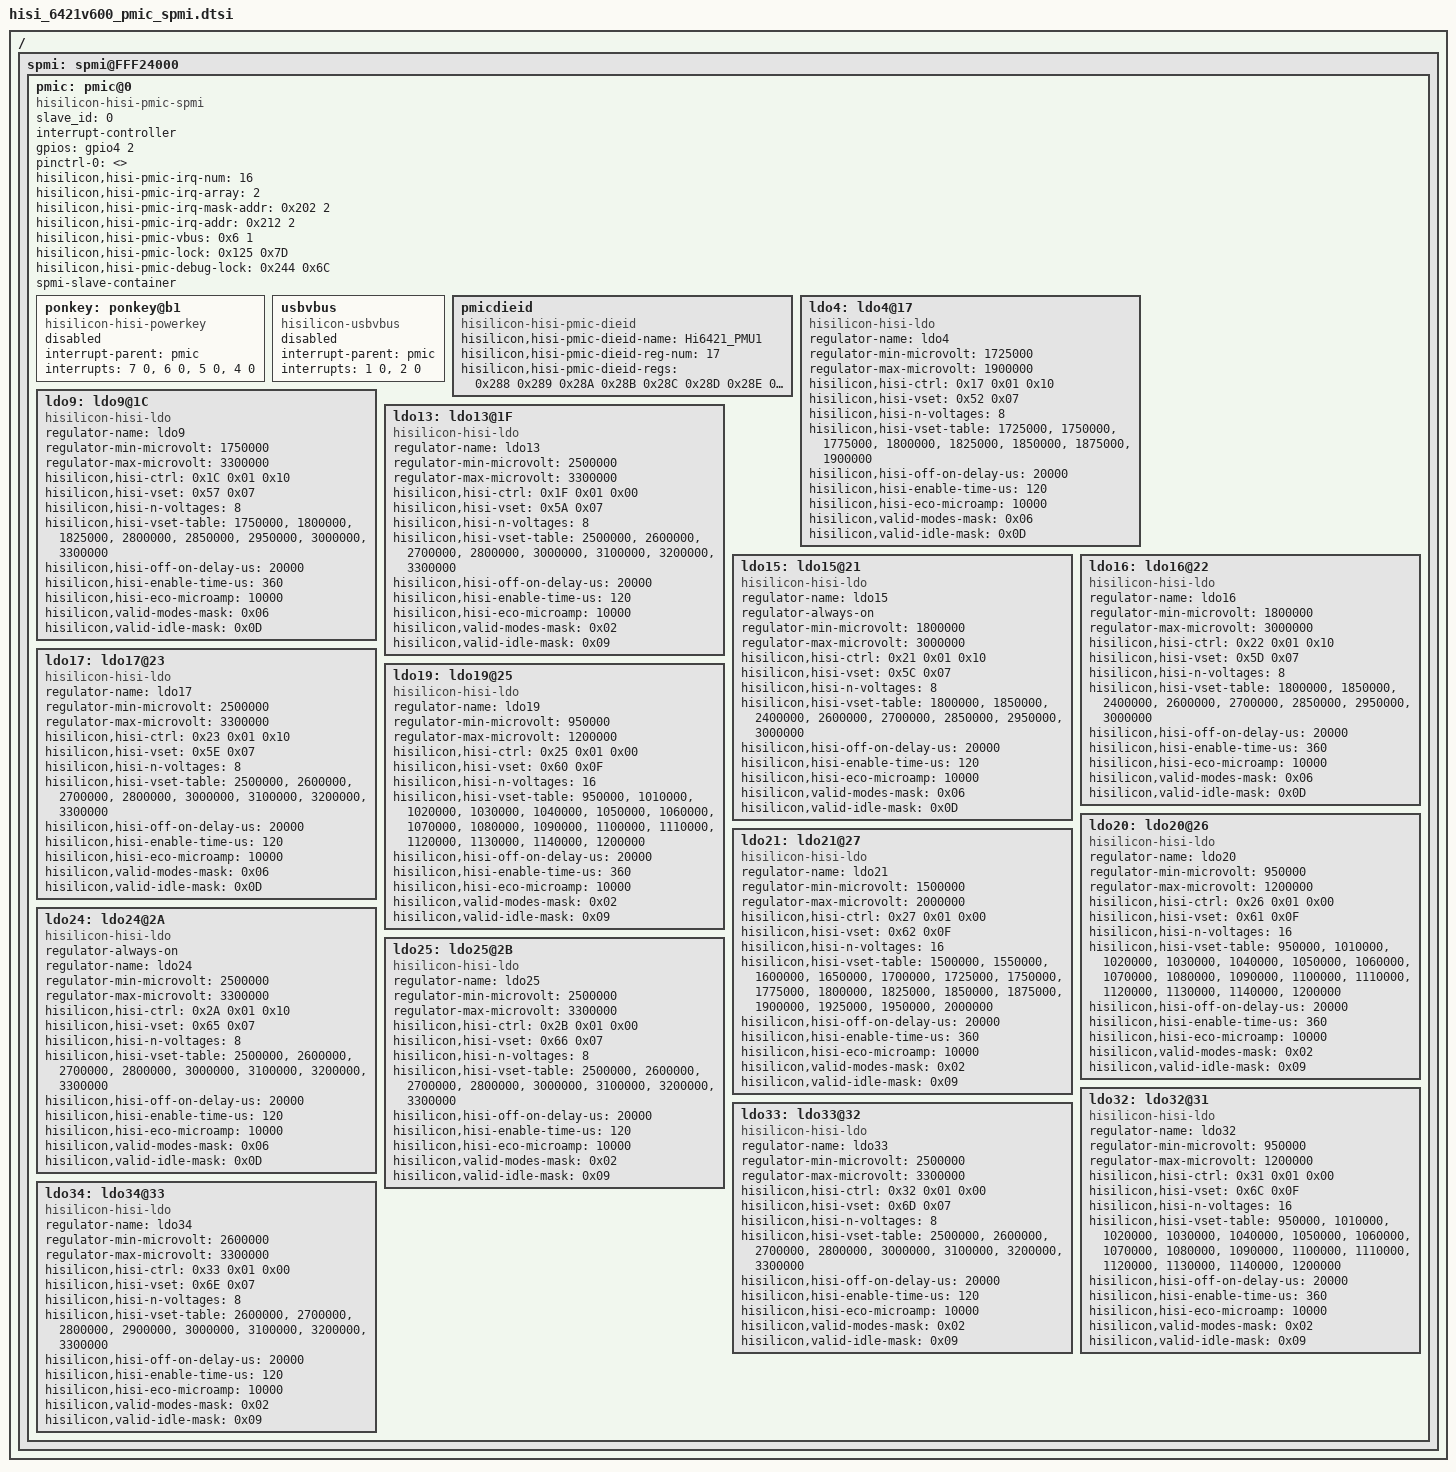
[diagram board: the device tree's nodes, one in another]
/*
 *  Copyright (C) 2012-2013 Linaro Ltd.
 *
 *  This program is free software; you can redistribute it and/or modify
 *  it under the terms of the GNU General Public License version 2 as
 *  publishhed by the Free Software Foundation.
 */
 /*hisilicon,valid-modes-mask:
*#define REGULATOR_MODE_FAST                     0x1
*#define REGULATOR_MODE_NORMAL                   0x2
*#define REGULATOR_MODE_IDLE                     0x4
*#define REGULATOR_MODE_STANDBY                  0x8
*/
/*hisilicon,valid-idle-mask:
*#define REGULATOR_CHANGE_VOLTAGE        0x1
*#define REGULATOR_CHANGE_CURRENT        0x2
*#define REGULATOR_CHANGE_MODE           0x4
*#define REGULATOR_CHANGE_STATUS         0x8
*#define REGULATOR_CHANGE_DRMS           0x10
*#define REGULATOR_CHANGE_BYPASS         0x20
*/
/ {
	spmi: spmi@FFF24000 {
		pmic: pmic@0 {
			compatible = "hisilicon-hisi-pmic-spmi";
			slave_id = <0>;
			#interrupt-cells = <2>;
			interrupt-controller;
			gpios = <&gpio4 2 0>;
			pinctrl-names = "default";
			pinctrl-0 = <>;
			hisilicon,hisi-pmic-irq-num = <16>;/*hisi irq number*/
			hisilicon,hisi-pmic-irq-array = <2>;/*hisi irq array*/
			hisilicon,hisi-pmic-irq-mask-addr = <0x202 2>;/*hisi irq mask addr*/
			hisilicon,hisi-pmic-irq-addr = <0x212 2>;/*hisi irq addr*/
			hisilicon,hisi-pmic-vbus = <0x6 1>;/*vbus status addr and bit*/
			hisilicon,hisi-pmic-lock = <0x125 0x7D>; /*lock: <addr value>*/
			hisilicon,hisi-pmic-debug-lock = <0x244 0x6C>;/*debug-lock: <addr value>*/
			spmi-slave-container;/*spmi-dev-container;*/

			ponkey:ponkey@b1{
					compatible = "hisilicon-hisi-powerkey";
					interrupt-parent = <&pmic>;
					interrupts = <7 0>, <6 0>, <5 0>, <4 0>;
					interrupt-names = "down", "up", "hold 1s", "hold 6s";
					status = "disabled";
			};

			usbvbus {
				compatible = "hisilicon-usbvbus";
				interrupt-parent = <&pmic>;
				interrupts = <1 0>, <2 0>;
				interrupt-names = "connect", "disconnect";
				status = "disabled";
			};

			pmicdieid {
				compatible = "hisilicon-hisi-pmic-dieid";
				hisilicon,hisi-pmic-dieid-name = "Hi6421_PMU1"; /*dieid: <chip name>*/
				hisilicon,hisi-pmic-dieid-reg-num = <17>; /*dieid: <register number>*/
				hisilicon,hisi-pmic-dieid-regs = <0x288 0x289 0x28A 0x28B 0x28C 0x28D 0x28E 0x28F 0x290 0x291 0x292 0x293 0x294 0x295 0x296 0x297 0x298>; /*dieid: <addr value>*/
			};

			ldo4: ldo4@17 {
				compatible = "hisilicon-hisi-ldo";
				regulator-name = "ldo4";
				regulator-min-microvolt = <1725000>;
				regulator-max-microvolt = <1900000>;
				hisilicon,hisi-ctrl = <0x17 0x01 0x10>;/*ctrl_reg、enable_mask、eco_mode_mask*/
				hisilicon,hisi-vset = <0x52 0x07>;
				hisilicon,hisi-n-voltages = <8>;
				hisilicon,hisi-vset-table = <1725000>, <1750000>,
											<1775000>, <1800000>,
											<1825000>, <1850000>,
											<1875000>, <1900000>;
				hisilicon,hisi-off-on-delay-us = <20000>;
				hisilicon,hisi-enable-time-us = <120>;
				hisilicon,hisi-eco-microamp = <10000>;
				hisilicon,valid-modes-mask = <0x06>;
				hisilicon,valid-idle-mask = <0x0D>;
			};

			ldo9: ldo9@1C {
				compatible = "hisilicon-hisi-ldo";
				regulator-name = "ldo9";
				regulator-min-microvolt = <1750000>;
				regulator-max-microvolt = <3300000>;
				hisilicon,hisi-ctrl = <0x1C 0x01 0x10>;
				hisilicon,hisi-vset = <0x57 0x07>;
				hisilicon,hisi-n-voltages = <8>;
				hisilicon,hisi-vset-table = <1750000>, <1800000>,
											<1825000>, <2800000>,
											<2850000>, <2950000>,
											<3000000>, <3300000>;
				hisilicon,hisi-off-on-delay-us = <20000>;
				hisilicon,hisi-enable-time-us = <360>;
				hisilicon,hisi-eco-microamp = <10000>;
				hisilicon,valid-modes-mask = <0x06>;
				hisilicon,valid-idle-mask = <0x0D>;
			};

			ldo13: ldo13@1F {
				compatible = "hisilicon-hisi-ldo";
				regulator-name = "ldo13";
				regulator-min-microvolt = <2500000>;
				regulator-max-microvolt = <3300000>;
				hisilicon,hisi-ctrl = <0x1F 0x01 0x00>;
				hisilicon,hisi-vset = <0x5A 0x07>;
				hisilicon,hisi-n-voltages = <8>;
				hisilicon,hisi-vset-table = <2500000>, <2600000>,
											<2700000>, <2800000>,
											<3000000>, <3100000>,
											<3200000>, <3300000>;
				hisilicon,hisi-off-on-delay-us = <20000>;
				hisilicon,hisi-enable-time-us = <120>;
				hisilicon,hisi-eco-microamp = <10000>;
				hisilicon,valid-modes-mask = <0x02>;
				hisilicon,valid-idle-mask = <0x09>;
			};


			ldo15: ldo15@21 {
				compatible = "hisilicon-hisi-ldo";
				regulator-name = "ldo15";
				regulator-always-on;
				regulator-min-microvolt = <1800000>;
				regulator-max-microvolt = <3000000>;
				hisilicon,hisi-ctrl = <0x21 0x01 0x10>;
				hisilicon,hisi-vset = <0x5C 0x07>;
				hisilicon,hisi-n-voltages = <8>;
				hisilicon,hisi-vset-table = <1800000>, <1850000>,
											<2400000>, <2600000>,
											<2700000>, <2850000>,
											<2950000>, <3000000>;
				hisilicon,hisi-off-on-delay-us = <20000>;
				hisilicon,hisi-enable-time-us = <120>;
				hisilicon,hisi-eco-microamp = <10000>;
				hisilicon,valid-modes-mask = <0x06>;
				hisilicon,valid-idle-mask = <0x0D>;
			};

			ldo16: ldo16@22 {
				compatible = "hisilicon-hisi-ldo";
				regulator-name = "ldo16";
				regulator-min-microvolt = <1800000>;
				regulator-max-microvolt = <3000000>;
				hisilicon,hisi-ctrl = <0x22 0x01 0x10>;
				hisilicon,hisi-vset = <0x5D 0x07>;
				hisilicon,hisi-n-voltages = <8>;
				hisilicon,hisi-vset-table = <1800000>, <1850000>,
											<2400000>, <2600000>,
											<2700000>, <2850000>,
											<2950000>, <3000000>;
				hisilicon,hisi-off-on-delay-us = <20000>;
				hisilicon,hisi-enable-time-us = <360>;
				hisilicon,hisi-eco-microamp = <10000>;
				hisilicon,valid-modes-mask = <0x06>;
				hisilicon,valid-idle-mask = <0x0D>;
			};

			ldo17: ldo17@23 {
				compatible = "hisilicon-hisi-ldo";
				regulator-name = "ldo17";
				regulator-min-microvolt = <2500000>;
				regulator-max-microvolt = <3300000>;
				hisilicon,hisi-ctrl = <0x23 0x01 0x10>;
				hisilicon,hisi-vset = <0x5E 0x07>;
				hisilicon,hisi-n-voltages = <8>;
				hisilicon,hisi-vset-table = <2500000>, <2600000>,
											<2700000>, <2800000>,
											<3000000>, <3100000>,
											<3200000>, <3300000>;
				hisilicon,hisi-off-on-delay-us = <20000>;
				hisilicon,hisi-enable-time-us = <120>;
				hisilicon,hisi-eco-microamp = <10000>;
				hisilicon,valid-modes-mask = <0x06>;
				hisilicon,valid-idle-mask = <0x0D>;
			};

			ldo19: ldo19@25 {
				compatible = "hisilicon-hisi-ldo";
				regulator-name = "ldo19";
				regulator-min-microvolt = <950000>;
				regulator-max-microvolt = <1200000>;
				hisilicon,hisi-ctrl = <0x25 0x01 0x00>;
				hisilicon,hisi-vset = <0x60 0x0F>;
				hisilicon,hisi-n-voltages = <16>;
				hisilicon,hisi-vset-table = <950000>,  <1010000>,
											<1020000>,  <1030000>,
											<1040000>, <1050000>,
											<1060000>, <1070000>,
											<1080000>, <1090000>,
											<1100000>, <1110000>,
											<1120000>, <1130000>,
											<1140000>, <1200000>;
				hisilicon,hisi-off-on-delay-us = <20000>;
				hisilicon,hisi-enable-time-us = <360>;
				hisilicon,hisi-eco-microamp = <10000>;
				hisilicon,valid-modes-mask = <0x02>;
				hisilicon,valid-idle-mask = <0x09>;
			};

			ldo20: ldo20@26 {
				compatible = "hisilicon-hisi-ldo";
				regulator-name = "ldo20";
				regulator-min-microvolt = <950000>;
				regulator-max-microvolt = <1200000>;
				hisilicon,hisi-ctrl = <0x26 0x01 0x00>;
				hisilicon,hisi-vset = <0x61 0x0F>;
				hisilicon,hisi-n-voltages = <16>;
				hisilicon,hisi-vset-table = <950000>,  <1010000>,
											<1020000>,  <1030000>,
											<1040000>, <1050000>,
											<1060000>, <1070000>,
											<1080000>, <1090000>,
											<1100000>, <1110000>,
											<1120000>, <1130000>,
											<1140000>, <1200000>;
				hisilicon,hisi-off-on-delay-us = <20000>;
				hisilicon,hisi-enable-time-us = <360>;
				hisilicon,hisi-eco-microamp = <10000>;
				hisilicon,valid-modes-mask = <0x02>;
				hisilicon,valid-idle-mask = <0x09>;
			};

			ldo21: ldo21@27 {
				compatible = "hisilicon-hisi-ldo";
				regulator-name = "ldo21";
				regulator-min-microvolt = <1500000>;
				regulator-max-microvolt = <2000000>;
				hisilicon,hisi-ctrl = <0x27 0x01 0x00>;
				hisilicon,hisi-vset = <0x62 0x0F>;
				hisilicon,hisi-n-voltages = <16>;
				hisilicon,hisi-vset-table =  <1500000>,  <1550000>,
											<1600000>,  <1650000>,
											<1700000>, <1725000>,
											<1750000>, <1775000>,
											<1800000>, <1825000>,
											<1850000>, <1875000>,
											<1900000>, <1925000>,
											<1950000>, <2000000>;
				hisilicon,hisi-off-on-delay-us = <20000>;
				hisilicon,hisi-enable-time-us = <360>;
				hisilicon,hisi-eco-microamp = <10000>;
				hisilicon,valid-modes-mask = <0x02>;
				hisilicon,valid-idle-mask = <0x09>;
			};

			ldo24: ldo24@2A {
				compatible = "hisilicon-hisi-ldo";
				regulator-always-on;
				regulator-name = "ldo24";
				regulator-min-microvolt = <2500000>;
				regulator-max-microvolt = <3300000>;
				hisilicon,hisi-ctrl = <0x2A 0x01 0x10>;
				hisilicon,hisi-vset = <0x65 0x07>;
				hisilicon,hisi-n-voltages = <8>;
				hisilicon,hisi-vset-table = <2500000>, <2600000>,
											<2700000>, <2800000>,
											<3000000>, <3100000>,
											<3200000>, <3300000>;
				hisilicon,hisi-off-on-delay-us = <20000>;
				hisilicon,hisi-enable-time-us = <120>;
				hisilicon,hisi-eco-microamp = <10000>;
				hisilicon,valid-modes-mask = <0x06>;
				hisilicon,valid-idle-mask = <0x0D>;
			};


			ldo25: ldo25@2B {
				compatible = "hisilicon-hisi-ldo";
				regulator-name = "ldo25";
				regulator-min-microvolt = <2500000>;
				regulator-max-microvolt = <3300000>;
				hisilicon,hisi-ctrl = <0x2B 0x01 0x00>;
				hisilicon,hisi-vset = <0x66 0x07>;
				hisilicon,hisi-n-voltages = <8>;
				hisilicon,hisi-vset-table = <2500000>, <2600000>,
											<2700000>, <2800000>,
											<3000000>, <3100000>,
											<3200000>, <3300000>;
				hisilicon,hisi-off-on-delay-us = <20000>;
				hisilicon,hisi-enable-time-us = <120>;
				hisilicon,hisi-eco-microamp = <10000>;
				hisilicon,valid-modes-mask = <0x02>;
				hisilicon,valid-idle-mask = <0x09>;
			};

			ldo32: ldo32@31 {
				compatible = "hisilicon-hisi-ldo";
				regulator-name = "ldo32";
				regulator-min-microvolt = <950000>;
				regulator-max-microvolt = <1200000>;
				hisilicon,hisi-ctrl = <0x31 0x01 0x00>;
				hisilicon,hisi-vset = <0x6C 0x0F>;
				hisilicon,hisi-n-voltages = <16>;
				hisilicon,hisi-vset-table = <950000>,  <1010000>,
											<1020000>,  <1030000>,
											<1040000>, <1050000>,
											<1060000>, <1070000>,
											<1080000>, <1090000>,
											<1100000>, <1110000>,
											<1120000>, <1130000>,
											<1140000>, <1200000>;
				hisilicon,hisi-off-on-delay-us = <20000>;
				hisilicon,hisi-enable-time-us = <360>;
				hisilicon,hisi-eco-microamp = <10000>;
				hisilicon,valid-modes-mask = <0x02>;
				hisilicon,valid-idle-mask = <0x09>;
			};

			ldo33: ldo33@32 {
				compatible = "hisilicon-hisi-ldo";
				regulator-name = "ldo33";
				regulator-min-microvolt = <2500000>;
				regulator-max-microvolt = <3300000>;
				hisilicon,hisi-ctrl = <0x32 0x01 0x00>;
				hisilicon,hisi-vset = <0x6D 0x07>;
				hisilicon,hisi-n-voltages = <8>;
				hisilicon,hisi-vset-table = <2500000>, <2600000>,
											<2700000>, <2800000>,
											<3000000>, <3100000>,
											<3200000>, <3300000>;
				hisilicon,hisi-off-on-delay-us = <20000>;
				hisilicon,hisi-enable-time-us = <120>;
				hisilicon,hisi-eco-microamp = <10000>;
				hisilicon,valid-modes-mask = <0x02>;
				hisilicon,valid-idle-mask = <0x09>;
			};

			ldo34: ldo34@33 {
				compatible = "hisilicon-hisi-ldo";
				regulator-name = "ldo34";
				regulator-min-microvolt = <2600000>;
				regulator-max-microvolt = <3300000>;
				hisilicon,hisi-ctrl = <0x33 0x01 0x00>;
				hisilicon,hisi-vset = <0x6E 0x07>;
				hisilicon,hisi-n-voltages = <8>;
				hisilicon,hisi-vset-table = <2600000>, <2700000>,
											<2800000>, <2900000>,
											<3000000>, <3100000>,
											<3200000>, <3300000>;
				hisilicon,hisi-off-on-delay-us = <20000>;
				hisilicon,hisi-enable-time-us = <120>;
				hisilicon,hisi-eco-microamp = <10000>;
				hisilicon,valid-modes-mask = <0x02>;
				hisilicon,valid-idle-mask = <0x09>;
			};
		};/* end of pmic */
	};/*end of spmi*/
};
